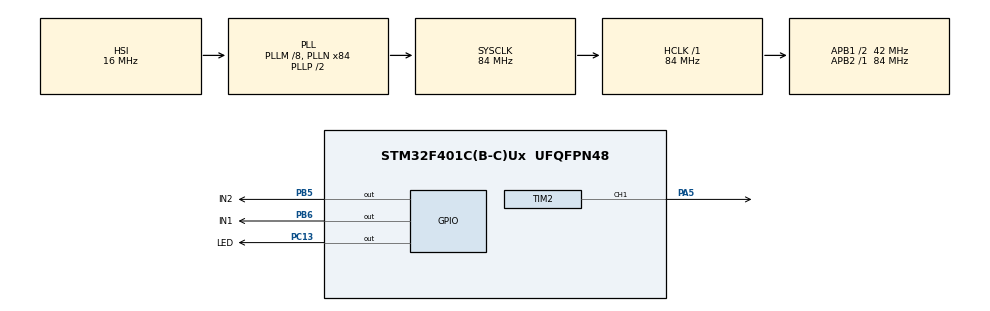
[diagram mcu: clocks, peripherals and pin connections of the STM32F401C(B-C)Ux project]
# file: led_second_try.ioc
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Mcu.Family=STM32F4
Mcu.Name=STM32F401C(B-C)Ux
Mcu.Package=UFQFPN48
NVIC.PriorityGroup=NVIC_PRIORITYGROUP_4
PA5.Signal=S_TIM2_CH1_ETR
PB5.GPIO_Label=IN2
PB5.Signal=GPIO_Output
PB6.GPIO_Label=IN1
PB6.Signal=GPIO_Output
PC13-ANTI_TAMP.GPIO_Label=LED
PC13-ANTI_TAMP.GPIO_ModeDefaultOutputPP=GPIO_MODE_OUTPUT_OD
PC13-ANTI_TAMP.GPIO_PuPd=GPIO_NOPULL
PC13-ANTI_TAMP.PinState=GPIO_PIN_SET
PC13-ANTI_TAMP.Signal=GPIO_Output
ProjectManager.HeapSize=0x200
ProjectManager.StackSize=0x400
ProjectManager.TargetToolchain=STM32CubeIDE
RCC.48MHZClocksFreq_Value=42000000
RCC.AHBFreq_Value=84000000
RCC.APB1CLKDivider=RCC_HCLK_DIV2
RCC.APB1Freq_Value=42000000
RCC.APB1TimFreq_Value=84000000
RCC.APB2Freq_Value=84000000
RCC.APB2TimFreq_Value=84000000
RCC.CortexFreq_Value=84000000
RCC.HCLKFreq_Value=84000000
RCC.HSE_VALUE=25000000
RCC.HSI_VALUE=16000000
RCC.LSE_VALUE=32768
RCC.PLLM=8
RCC.PLLN=84
RCC.SYSCLKFreq_VALUE=84000000
RCC.SYSCLKSource=RCC_SYSCLKSOURCE_PLLCLK
RCC.VCOOutputFreq_Value=168000000
SH.S_TIM2_CH1_ETR.0=TIM2_CH1,PWM Generation1 CH1
TIM2.Channel-PWM\ Generation1\ CH1=TIM_CHANNEL_1
TIM2.Period=255
board=custom

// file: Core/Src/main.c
/* USER CODE BEGIN Header */
/**
  ******************************************************************************
  * @file           : main.c
  * @brief          : Main program body
  ******************************************************************************
  * @attention
  *
  * Copyright (c) 2025 STMicroelectronics.
  * All rights reserved.
  *
  * This software is licensed under terms that can be found in the LICENSE file
  * in the root directory of this software component.
  * If no LICENSE file comes with this software, it is provided AS-IS.
  *
  ******************************************************************************
  */
/* USER CODE END Header */
#include "main.h"

/* USER CODE BEGIN Includes */
#include<stdio.h>
/* USER CODE END Includes */

TIM_HandleTypeDef htim2;

void SystemClock_Config(void);
static void MX_GPIO_Init(void);
static void MX_TIM2_Init(void);

int main(void)
{

  /* MCU Configuration--------------------------------------------------------*/

  /* Reset of all peripherals, Initializes the Flash interface and the Systick. */
  HAL_Init();

  /* Configure the system clock */
  SystemClock_Config();

  /* Initialize all configured peripherals */
  MX_GPIO_Init();
  MX_TIM2_Init();
  /* USER CODE BEGIN 2 */
  HAL_TIM_PWM_Start(&htim2,TIM_CHANNEL_1);
  printf("code starting");
  /* USER CODE END 2 */

  /* Infinite loop */
  /* USER CODE BEGIN WHILE */
  //uint32_t now = 0, last = 0, delay = 1000;
  while (1)
  {
	  HAL_GPIO_WritePin(GPIOB,IN1_Pin,1);
	  HAL_GPIO_WritePin(GPIOB,IN2_Pin,0);
	  __HAL_TIM_SET_COMPARE(&htim2,TIM_CHANNEL_1,255);
	  HAL_Delay(1000);

	  HAL_GPIO_WritePin(GPIOB,IN1_Pin,0);
	  HAL_GPIO_WritePin(GPIOB,IN2_Pin,1);
	  __HAL_TIM_SET_COMPARE(&htim2,TIM_CHANNEL_1,255);
	  HAL_Delay(1000);

	  }
    /* USER CODE END WHILE */

  }

void SystemClock_Config(void)
{
  RCC_OscInitTypeDef RCC_OscInitStruct = {0};
  RCC_ClkInitTypeDef RCC_ClkInitStruct = {0};

  /** Configure the main internal regulator output voltage
  */
  __HAL_RCC_PWR_CLK_ENABLE();
  __HAL_PWR_VOLTAGESCALING_CONFIG(PWR_REGULATOR_VOLTAGE_SCALE2);

  /** Initializes the RCC Oscillators according to the specified parameters
  * in the RCC_OscInitTypeDef structure.
  */
  RCC_OscInitStruct.OscillatorType = RCC_OSCILLATORTYPE_HSI;
  RCC_OscInitStruct.HSIState = RCC_HSI_ON;
  RCC_OscInitStruct.HSICalibrationValue = RCC_HSICALIBRATION_DEFAULT;
  RCC_OscInitStruct.PLL.PLLState = RCC_PLL_ON;
  RCC_OscInitStruct.PLL.PLLSource = RCC_PLLSOURCE_HSI;
  RCC_OscInitStruct.PLL.PLLM = 8;
  RCC_OscInitStruct.PLL.PLLN = 84;
  RCC_OscInitStruct.PLL.PLLP = RCC_PLLP_DIV2;
  RCC_OscInitStruct.PLL.PLLQ = 4;
  if (HAL_RCC_OscConfig(&RCC_OscInitStruct) != HAL_OK)
  {
    Error_Handler();
  }

  /** Initializes the CPU, AHB and APB buses clocks
  */
  RCC_ClkInitStruct.ClockType = RCC_CLOCKTYPE_HCLK|RCC_CLOCKTYPE_SYSCLK
                              |RCC_CLOCKTYPE_PCLK1|RCC_CLOCKTYPE_PCLK2;
  RCC_ClkInitStruct.SYSCLKSource = RCC_SYSCLKSOURCE_PLLCLK;
  RCC_ClkInitStruct.AHBCLKDivider = RCC_SYSCLK_DIV1;
  RCC_ClkInitStruct.APB1CLKDivider = RCC_HCLK_DIV2;
  RCC_ClkInitStruct.APB2CLKDivider = RCC_HCLK_DIV1;

  if (HAL_RCC_ClockConfig(&RCC_ClkInitStruct, FLASH_LATENCY_2) != HAL_OK)
  {
    Error_Handler();
  }
}

static void MX_TIM2_Init(void)
{

  TIM_MasterConfigTypeDef sMasterConfig = {0};
  TIM_OC_InitTypeDef sConfigOC = {0};

  htim2.Instance = TIM2;
  htim2.Init.Prescaler = 0;
  htim2.Init.CounterMode = TIM_COUNTERMODE_UP;
  htim2.Init.Period = 255;
  htim2.Init.ClockDivision = TIM_CLOCKDIVISION_DIV1;
  htim2.Init.AutoReloadPreload = TIM_AUTORELOAD_PRELOAD_DISABLE;
  if (HAL_TIM_PWM_Init(&htim2) != HAL_OK)
  {
    Error_Handler();
  }
  sMasterConfig.MasterOutputTrigger = TIM_TRGO_RESET;
  sMasterConfig.MasterSlaveMode = TIM_MASTERSLAVEMODE_DISABLE;
  if (HAL_TIMEx_MasterConfigSynchronization(&htim2, &sMasterConfig) != HAL_OK)
  {
    Error_Handler();
  }
  sConfigOC.OCMode = TIM_OCMODE_PWM1;
  sConfigOC.Pulse = 0;
  sConfigOC.OCPolarity = TIM_OCPOLARITY_HIGH;
  sConfigOC.OCFastMode = TIM_OCFAST_DISABLE;
  if (HAL_TIM_PWM_ConfigChannel(&htim2, &sConfigOC, TIM_CHANNEL_1) != HAL_OK)
  {
    Error_Handler();
  }
  HAL_TIM_MspPostInit(&htim2);

}

static void MX_GPIO_Init(void)
{
  GPIO_InitTypeDef GPIO_InitStruct = {0};

  /* GPIO Ports Clock Enable */
  __HAL_RCC_GPIOC_CLK_ENABLE();
  __HAL_RCC_GPIOA_CLK_ENABLE();
  __HAL_RCC_GPIOB_CLK_ENABLE();

  /*Configure GPIO pin Output Level */
  HAL_GPIO_WritePin(LED_GPIO_Port, LED_Pin, GPIO_PIN_SET);

  /*Configure GPIO pin Output Level */
  HAL_GPIO_WritePin(GPIOB, IN2_Pin|IN1_Pin, GPIO_PIN_RESET);

  /*Configure GPIO pin : LED_Pin */
  GPIO_InitStruct.Pin = LED_Pin;
  GPIO_InitStruct.Mode = GPIO_MODE_OUTPUT_OD;
  GPIO_InitStruct.Pull = GPIO_NOPULL;
  GPIO_InitStruct.Speed = GPIO_SPEED_FREQ_LOW;
  HAL_GPIO_Init(LED_GPIO_Port, &GPIO_InitStruct);

  /*Configure GPIO pins : IN2_Pin IN1_Pin */
  GPIO_InitStruct.Pin = IN2_Pin|IN1_Pin;
  GPIO_InitStruct.Mode = GPIO_MODE_OUTPUT_PP;
  GPIO_InitStruct.Pull = GPIO_NOPULL;
  GPIO_InitStruct.Speed = GPIO_SPEED_FREQ_LOW;
  HAL_GPIO_Init(GPIOB, &GPIO_InitStruct);

}

void Error_Handler(void)
{
  __disable_irq();
  while (1)
  {
  }
}
